# CC430F5123 register map
Registers are 16-bit, read-write, reset 0x0 unless marked. A register's access mark holds for its fields unless they carry their own. Offsets are from the block's base; [hi:lo] are bit positions; {n}, {i} and the like mark numbered series.

## Timer1_A3
Base 0x00000000
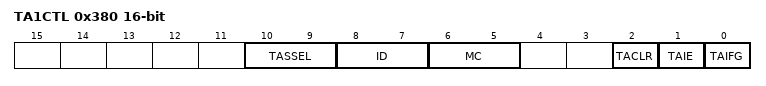
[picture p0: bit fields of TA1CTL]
0x380 TA1CTL — Timer1_A3 Control
  [10:9] TASSEL — Timer A clock source select 1
    0=Timer A clock source select: 0 - TACLK; 1=Timer A clock source select: 1 - ACLK; 2=Timer A clock source select: 2 - SMCLK; 3=Timer A clock source select: 3 - INCLK
  [8:7] ID — Timer A clock input divider 1
    0=Timer A input divider: 0 - /1; 1=Timer A input divider: 1 - /2; 2=Timer A input divider: 2 - /4; 3=Timer A input divider: 3 - /8
  [6:5] MC — Timer A mode control 1
    0=Timer A mode control: 0 - Stop; 1=Timer A mode control: 1 - Up to CCR0; 2=Timer A mode control: 2 - Continuous up; 3=Timer A mode control: 3 - Up/Down
  [2] TACLR — Timer A counter clear
  [1] TAIE — Timer A counter interrupt enable
  [0] TAIFG — Timer A counter interrupt flag
{0x382+2i} TA1CCTL{i} (i=0..2) — Timer1_A3 Capture/Compare Control {i}
  [16:15] CM — Capture mode 1
    0=Capture mode: 0 - disabled; 1=Capture mode: 1 - pos. edge; 2=Capture mode: 1 - neg. edge; 3=Capture mode: 1 - both edges
  [14:13] CCIS — Capture input select 1
    0=Capture input select: 0 - CCIxA; 1=Capture input select: 1 - CCIxB; 2=Capture input select: 2 - GND; 3=Capture input select: 3 - Vcc
  [11] SCS — Capture sychronize
  [10] SCCI — Latched capture signal (read)
  [8] CAP — Capture mode: 1 /Compare mode : 0
  [9:7] OUTMOD — Output mode 2
    0=PWM output mode: 0 - output only; 1=PWM output mode: 1 - set; 2=PWM output mode: 2 - PWM toggle/reset; 3=PWM output mode: 3 - PWM set/reset; 4=PWM output mode: 4 - toggle; 5=PWM output mode: 5 - Reset; 6=PWM output mode: 6 - PWM toggle/set; 7=PWM output mode: 7 - PWM reset/set
  [4] CCIE — Capture/compare interrupt enable
  [3] CCI — Capture input signal (read)
  [2] OUT — PWM Output signal if output mode 0
  [1] COV — Capture/compare overflow flag
  [0] CCIFG — Capture/compare interrupt flag
0x390 TA1R — Timer1_A3
{0x392+2i} TA1CCR{i} (i=0..2) — Timer1_A3 Capture/Compare {i}
0x3A0 TA1EX0 — Timer1_A3 Expansion Register 0
  [4:2] TAIDEX — Timer A Input divider expansion Bit: 0
    {v}=Timer A Input divider expansion : /{v+1} (v=0..7)
0x3AE TA1IV — Timer1_A3 Interrupt Vector Word

## UCS_Unified_System_Clock
Base 0x00000000
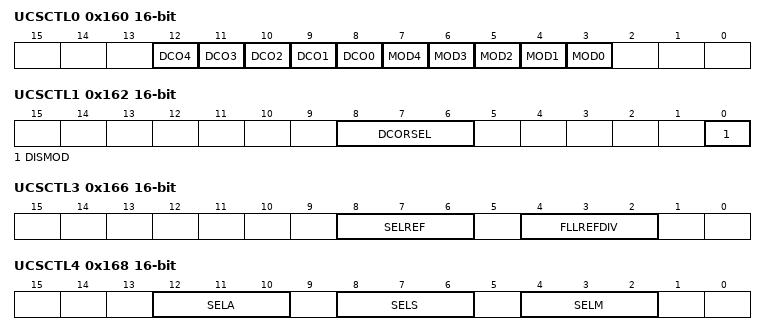
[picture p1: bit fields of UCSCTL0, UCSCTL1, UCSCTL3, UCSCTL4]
0x160 UCSCTL0 — UCS Control Register 0
  [n+8] DCO{n} (n=0..4) — DCO TAP Bit : {n}
  [n+3] MOD{n} (n=0..4) — Modulation Bit Counter Bit : {n}
0x162 UCSCTL1 — UCS Control Register 1
  [8:6] DCORSEL — DCO Freq. Range Select Bit : 0
  [0] DISMOD — Disable Modulation
0x164 UCSCTL2 — UCS Control Register 2
  [16:14] FLLD — Loop Divider Bit : 0
    0=Multiply Selected Loop Freq. 1; 1=Multiply Selected Loop Freq. 2; 2=Multiply Selected Loop Freq. 4; 3=Multiply Selected Loop Freq. 8; 4=Multiply Selected Loop Freq. 16; 5=Multiply Selected Loop Freq. 32; 6=Multiply Selected Loop Freq. 32; 7=Multiply Selected Loop Freq. 32
  [n] FLLN{n} (n=0..9) — FLL Multipier Bit : {n}
0x166 UCSCTL3 — UCS Control Register 3
  [8:6] SELREF — FLL Reference Clock Select Bit : 0
    {v}=FLL Reference Clock Select {v} (v=0..7)
  [4:2] FLLREFDIV — Reference Divider Bit : 0
    0=Reference Divider: f(LFCLK)/1; 1=Reference Divider: f(LFCLK)/2; 2=Reference Divider: f(LFCLK)/4; 3=Reference Divider: f(LFCLK)/8; 4=Reference Divider: f(LFCLK)/12; 5=Reference Divider: f(LFCLK)/16; 6=Reference Divider: f(LFCLK)/16; 7=Reference Divider: f(LFCLK)/16
0x168 UCSCTL4 — UCS Control Register 4
  [12:10] SELA — ACLK Source Select Bit: 0
    {v}=ACLK Source Select {v} (v=0..7)
  [8:6] SELS — SMCLK Source Select Bit: 0
    {v}=SMCLK Source Select {v} (v=0..7)
  [4:2] SELM — MCLK Source Select Bit: 0
    {v}=MCLK Source Select {v} (v=0..7)
0x16A UCSCTL5 — UCS Control Register 5
  [16:14] DIVPA — ACLK from Pin Divider Bit: 0
    {v}=ACLK from Pin Source Divider {v} (v=0..7)
  [12:10] DIVA — ACLK Divider Bit: 0
    {v}=ACLK Source Divider {v} (v=0..7)
  [8:6] DIVS — SMCLK Divider Bit: 0
    {v}=SMCLK Source Divider {v} (v=0..7)
  [4:2] DIVM — MCLK Divider Bit: 0
    {v}=MCLK Source Divider {v} (v=0..7)
0x16C UCSCTL6 — UCS Control Register 6
  [8] XT2OFF — High Frequency Oscillator 2 (XT2) disable
  [8:7] XT1DRIVE — XT1 Drive Level mode Bit 0
    {v}=XT1 Drive Level mode: {v} (v=0..3)
  [5] XTS — 1: Selects high-freq. oscillator
  [4] XT1BYPASS — XT1 bypass mode : 0: internal 1:sourced from external pin
  [4:3] XCAP — XIN/XOUT Cap Bit: 0
    {v}=XIN/XOUT Cap {v} (v=0..3)
  [1] SMCLKOFF
  [0] XT1OFF — High Frequency Oscillator 1 (XT1) disable
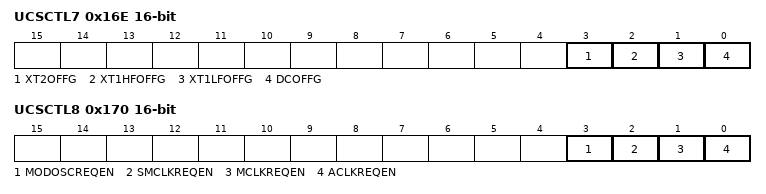
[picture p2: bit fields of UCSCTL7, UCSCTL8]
0x16E UCSCTL7 — UCS Control Register 7
  [3] XT2OFFG — High Frequency Oscillator 2 Fault Flag
  [2] XT1HFOFFG — XT1 High Frequency Oscillator 1 Fault Flag
  [1] XT1LFOFFG — XT1 Low Frequency Oscillator Fault Flag
  [0] DCOFFG — DCO Fault Flag
0x170 UCSCTL8 — UCS Control Register 8
  [3] MODOSCREQEN — MODOSC Clock Request Enable
  [2] SMCLKREQEN — SMCLK Clock Request Enable
  [1] MCLKREQEN — MCLK Clock Request Enable
  [0] ACLKREQEN — ACLK Clock Request Enable
